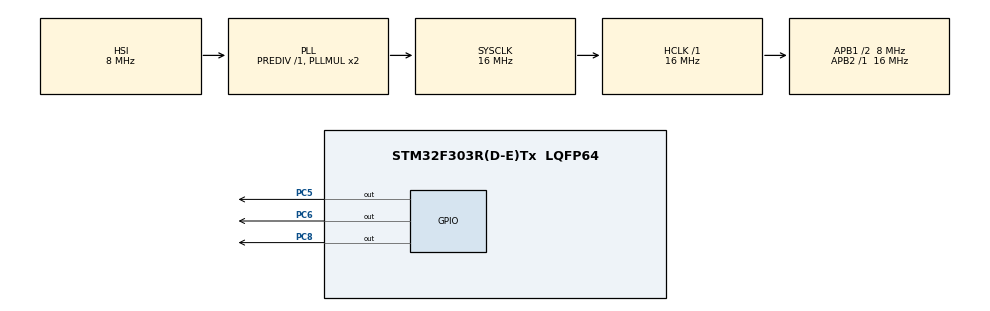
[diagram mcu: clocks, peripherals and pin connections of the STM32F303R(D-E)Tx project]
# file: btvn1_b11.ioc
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Mcu.Family=STM32F3
Mcu.Name=STM32F303R(D-E)Tx
Mcu.Package=LQFP64
NVIC.PriorityGroup=NVIC_PRIORITYGROUP_4
NVIC.TIM4_IRQn=true\:0\:0\:false\:false\:true\:true\:true
PA13.Mode=Serial_Wire
PA13.Signal=SYS_JTMS-SWDIO
PA14.Mode=Serial_Wire
PA14.Signal=SYS_JTCK-SWCLK
PC5.Signal=GPIO_Output
PC6.Signal=GPIO_Output
PC8.Signal=GPIO_Output
ProjectManager.HeapSize=0x200
ProjectManager.StackSize=0x400
ProjectManager.TargetToolchain=STM32CubeIDE
RCC.AHBFreq_Value=16000000
RCC.APB1CLKDivider=RCC_HCLK_DIV2
RCC.APB1Freq_Value=8000000
RCC.APB1TimFreq_Value=16000000
RCC.APB2Freq_Value=16000000
RCC.APB2TimFreq_Value=16000000
RCC.CortexFreq_Value=16000000
RCC.HCLKFreq_Value=16000000
RCC.HSE_VALUE=8000000
RCC.HSI_VALUE=8000000
RCC.LSE_VALUE=32768
RCC.SYSCLKFreq_VALUE=16000000
RCC.SYSCLKSourceVirtual=RCC_SYSCLKSOURCE_PLLCLK
RCC.USBFreq_Value=16000000
TIM4.Period=999
TIM4.Prescaler=15999
VP_TIM4_VS_ClockSourceINT.Mode=Internal
board=custom

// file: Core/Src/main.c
/* USER CODE BEGIN Header */
/**
  ******************************************************************************
  * @file           : main.c
  * @brief          : Main program body
  ******************************************************************************
  * @attention
  *
  * <h2><center>&copy; Copyright (c) 2021 STMicroelectronics.
  * All rights reserved.</center></h2>
  *
  * This software component is licensed by ST under BSD 3-Clause license,
  * the "License"; You may not use this file except in compliance with the
  * License. You may obtain a copy of the License at:
  *                        opensource.org/licenses/BSD-3-Clause
  *
  ******************************************************************************
  */
/* USER CODE END Header */
#include "main.h"

TIM_HandleTypeDef htim4;

/* USER CODE BEGIN PV */
uint8_t count = 0;
/* USER CODE END PV */

void SystemClock_Config(void);
static void MX_GPIO_Init(void);
static void MX_TIM4_Init(void);

/* USER CODE BEGIN 0 */
void HAL_TIM_PeriodElapsedCallback(TIM_HandleTypeDef *htim){
	count ++;
}
/* USER CODE END 0 */

int main(void)
{

  /* MCU Configuration--------------------------------------------------------*/

  /* Reset of all peripherals, Initializes the Flash interface and the Systick. */
  HAL_Init();

  /* Configure the system clock */
  SystemClock_Config();

  /* Initialize all configured peripherals */
  MX_GPIO_Init();
  MX_TIM4_Init();
  /* USER CODE BEGIN 2 */
HAL_TIM_Base_Start_IT(&htim4);
  /* USER CODE END 2 */

  /* Infinite loop */
  /* USER CODE BEGIN WHILE */
  while (1)
  {
	  if(count <= 4){
		  HAL_GPIO_WritePin(GPIOC, GPIO_PIN_8,GPIO_PIN_SET);
		  HAL_GPIO_WritePin(GPIOC, GPIO_PIN_6,GPIO_PIN_RESET);
		  HAL_GPIO_WritePin(GPIOC, GPIO_PIN_5,GPIO_PIN_RESET);
	  }
	  else if(count <= 7){
		  HAL_GPIO_WritePin(GPIOC, GPIO_PIN_8,GPIO_PIN_RESET);
		  HAL_GPIO_WritePin(GPIOC, GPIO_PIN_6,GPIO_PIN_SET);
		  HAL_GPIO_WritePin(GPIOC, GPIO_PIN_5,GPIO_PIN_RESET);
	  }
	  else if(count <= 14){
		  HAL_GPIO_WritePin(GPIOC, GPIO_PIN_8,GPIO_PIN_RESET);
		  HAL_GPIO_WritePin(GPIOC, GPIO_PIN_6,GPIO_PIN_RESET);
		  HAL_GPIO_WritePin(GPIOC, GPIO_PIN_5,GPIO_PIN_SET);
	  }
	  else{
		  count = 0;
	  }
    /* USER CODE END WHILE */

  }
}

void SystemClock_Config(void)
{
  RCC_OscInitTypeDef RCC_OscInitStruct = {0};
  RCC_ClkInitTypeDef RCC_ClkInitStruct = {0};
  RCC_PeriphCLKInitTypeDef PeriphClkInit = {0};

  /** Initializes the RCC Oscillators according to the specified parameters
  * in the RCC_OscInitTypeDef structure.
  */
  RCC_OscInitStruct.OscillatorType = RCC_OSCILLATORTYPE_HSI;
  RCC_OscInitStruct.HSIState = RCC_HSI_ON;
  RCC_OscInitStruct.HSICalibrationValue = RCC_HSICALIBRATION_DEFAULT;
  RCC_OscInitStruct.PLL.PLLState = RCC_PLL_ON;
  RCC_OscInitStruct.PLL.PLLSource = RCC_PLLSOURCE_HSI;
  RCC_OscInitStruct.PLL.PLLMUL = RCC_PLL_MUL2;
  RCC_OscInitStruct.PLL.PREDIV = RCC_PREDIV_DIV1;
  if (HAL_RCC_OscConfig(&RCC_OscInitStruct) != HAL_OK)
  {
    Error_Handler();
  }
  /** Initializes the CPU, AHB and APB buses clocks
  */
  RCC_ClkInitStruct.ClockType = RCC_CLOCKTYPE_HCLK|RCC_CLOCKTYPE_SYSCLK
                              |RCC_CLOCKTYPE_PCLK1|RCC_CLOCKTYPE_PCLK2;
  RCC_ClkInitStruct.SYSCLKSource = RCC_SYSCLKSOURCE_PLLCLK;
  RCC_ClkInitStruct.AHBCLKDivider = RCC_SYSCLK_DIV1;
  RCC_ClkInitStruct.APB1CLKDivider = RCC_HCLK_DIV2;
  RCC_ClkInitStruct.APB2CLKDivider = RCC_HCLK_DIV1;

  if (HAL_RCC_ClockConfig(&RCC_ClkInitStruct, FLASH_LATENCY_0) != HAL_OK)
  {
    Error_Handler();
  }
  PeriphClkInit.PeriphClockSelection = RCC_PERIPHCLK_TIM34;
  PeriphClkInit.Tim34ClockSelection = RCC_TIM34CLK_HCLK;
  if (HAL_RCCEx_PeriphCLKConfig(&PeriphClkInit) != HAL_OK)
  {
    Error_Handler();
  }
}

static void MX_TIM4_Init(void)
{

  TIM_ClockConfigTypeDef sClockSourceConfig = {0};
  TIM_MasterConfigTypeDef sMasterConfig = {0};

  htim4.Instance = TIM4;
  htim4.Init.Prescaler = 15999;
  htim4.Init.CounterMode = TIM_COUNTERMODE_UP;
  htim4.Init.Period = 999;
  htim4.Init.ClockDivision = TIM_CLOCKDIVISION_DIV1;
  htim4.Init.AutoReloadPreload = TIM_AUTORELOAD_PRELOAD_DISABLE;
  if (HAL_TIM_Base_Init(&htim4) != HAL_OK)
  {
    Error_Handler();
  }
  sClockSourceConfig.ClockSource = TIM_CLOCKSOURCE_INTERNAL;
  if (HAL_TIM_ConfigClockSource(&htim4, &sClockSourceConfig) != HAL_OK)
  {
    Error_Handler();
  }
  sMasterConfig.MasterOutputTrigger = TIM_TRGO_RESET;
  sMasterConfig.MasterSlaveMode = TIM_MASTERSLAVEMODE_DISABLE;
  if (HAL_TIMEx_MasterConfigSynchronization(&htim4, &sMasterConfig) != HAL_OK)
  {
    Error_Handler();
  }

}

static void MX_GPIO_Init(void)
{
  GPIO_InitTypeDef GPIO_InitStruct = {0};

  /* GPIO Ports Clock Enable */
  __HAL_RCC_GPIOC_CLK_ENABLE();
  __HAL_RCC_GPIOA_CLK_ENABLE();

  /*Configure GPIO pin Output Level */
  HAL_GPIO_WritePin(GPIOC, GPIO_PIN_5|GPIO_PIN_6|GPIO_PIN_8, GPIO_PIN_RESET);

  /*Configure GPIO pins : PC5 PC6 PC8 */
  GPIO_InitStruct.Pin = GPIO_PIN_5|GPIO_PIN_6|GPIO_PIN_8;
  GPIO_InitStruct.Mode = GPIO_MODE_OUTPUT_PP;
  GPIO_InitStruct.Pull = GPIO_NOPULL;
  GPIO_InitStruct.Speed = GPIO_SPEED_FREQ_LOW;
  HAL_GPIO_Init(GPIOC, &GPIO_InitStruct);

}

void Error_Handler(void)
{
  __disable_irq();
  while (1)
  {
  }
}

/************************ (C) COPYRIGHT STMicroelectronics *****END OF FILE****/
